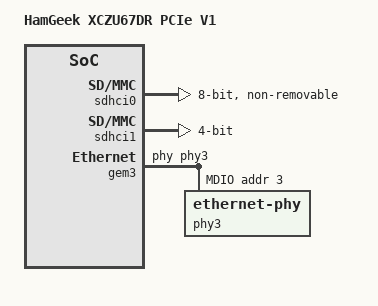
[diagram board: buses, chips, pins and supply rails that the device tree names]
/ {
    model = "HamGeek XCZU67DR PCIe V1";
    aliases {
        mmc0 = &sdhci1;
        mmc1 = &sdhci0;
    };
    reserved-memory {
        #address-cells = <2>;
        #size-cells = <2>;
        ranges;
        linux,cma {
            compatible = "shared-dma-pool";
            reusable;
            size = <0x0 0x20000000>;
            alignment = <0x0 0x2000>;
            alloc-ranges = <0x0 0x0 0x0 0x80000000>;
            linux,cma-default;
        };
    };
};

&sdhci0 {
    bus-width = <8>;
    non-removable;
};

&sdhci1 {
    bus-width = <4>;
    no-1-8-v;
    max-frequency = <50000000>;
    disable-wp;
};

&gem3 {
    phy-handle = <&phy3>;
    mdio {
        #address-cells = <1>;
        #size-cells = <0>;
        phy3: ethernet-phy@3 {
            reg = <3>;
        };
    };
};
